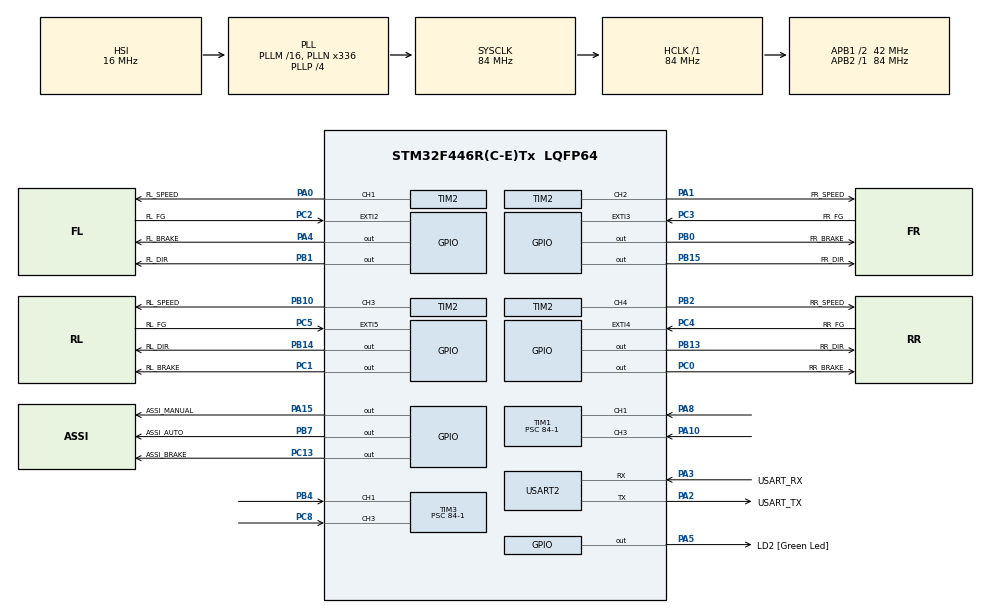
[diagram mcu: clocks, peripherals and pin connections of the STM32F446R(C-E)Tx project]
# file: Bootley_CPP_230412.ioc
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Dma.Request0=TIM1_CH1
Dma.Request1=TIM1_CH2
Dma.Request2=TIM1_CH3
Dma.Request3=TIM1_CH4/TRIG/COM
Dma.Request4=TIM3_CH1/TRIG
Dma.Request5=TIM3_CH2
Dma.Request6=TIM3_CH3
Dma.Request7=TIM3_CH4/UP
Dma.TIM1_CH1.0.Direction=DMA_PERIPH_TO_MEMORY
Dma.TIM1_CH1.0.FIFOMode=DMA_FIFOMODE_DISABLE
Dma.TIM1_CH1.0.Instance=DMA2_Stream1
Dma.TIM1_CH1.0.MemDataAlignment=DMA_MDATAALIGN_HALFWORD
Dma.TIM1_CH1.0.MemInc=DMA_MINC_ENABLE
Dma.TIM1_CH1.0.Mode=DMA_CIRCULAR
Dma.TIM1_CH1.0.PeriphDataAlignment=DMA_PDATAALIGN_HALFWORD
Dma.TIM1_CH1.0.PeriphInc=DMA_PINC_DISABLE
Dma.TIM1_CH1.0.Priority=DMA_PRIORITY_LOW
Dma.TIM1_CH2.1.Direction=DMA_PERIPH_TO_MEMORY
Dma.TIM1_CH2.1.FIFOMode=DMA_FIFOMODE_DISABLE
Dma.TIM1_CH2.1.Instance=DMA2_Stream2
Dma.TIM1_CH2.1.MemDataAlignment=DMA_MDATAALIGN_HALFWORD
Dma.TIM1_CH2.1.MemInc=DMA_MINC_ENABLE
Dma.TIM1_CH2.1.Mode=DMA_CIRCULAR
Dma.TIM1_CH2.1.PeriphDataAlignment=DMA_PDATAALIGN_HALFWORD
Dma.TIM1_CH2.1.PeriphInc=DMA_PINC_DISABLE
Dma.TIM1_CH2.1.Priority=DMA_PRIORITY_LOW
Dma.TIM1_CH3.2.Direction=DMA_PERIPH_TO_MEMORY
Dma.TIM1_CH3.2.FIFOMode=DMA_FIFOMODE_DISABLE
Dma.TIM1_CH3.2.Instance=DMA2_Stream6
Dma.TIM1_CH3.2.MemDataAlignment=DMA_MDATAALIGN_HALFWORD
Dma.TIM1_CH3.2.MemInc=DMA_MINC_ENABLE
Dma.TIM1_CH3.2.Mode=DMA_CIRCULAR
Dma.TIM1_CH3.2.PeriphDataAlignment=DMA_PDATAALIGN_HALFWORD
Dma.TIM1_CH3.2.PeriphInc=DMA_PINC_DISABLE
Dma.TIM1_CH3.2.Priority=DMA_PRIORITY_LOW
Dma.TIM1_CH4/TRIG/COM.3.Direction=DMA_PERIPH_TO_MEMORY
Dma.TIM1_CH4/TRIG/COM.3.FIFOMode=DMA_FIFOMODE_DISABLE
Dma.TIM1_CH4/TRIG/COM.3.Instance=DMA2_Stream4
Dma.TIM1_CH4/TRIG/COM.3.MemDataAlignment=DMA_MDATAALIGN_HALFWORD
Dma.TIM1_CH4/TRIG/COM.3.MemInc=DMA_MINC_ENABLE
Dma.TIM1_CH4/TRIG/COM.3.Mode=DMA_CIRCULAR
Dma.TIM1_CH4/TRIG/COM.3.PeriphDataAlignment=DMA_PDATAALIGN_HALFWORD
Dma.TIM1_CH4/TRIG/COM.3.PeriphInc=DMA_PINC_DISABLE
Dma.TIM1_CH4/TRIG/COM.3.Priority=DMA_PRIORITY_LOW
Dma.TIM3_CH1/TRIG.4.Direction=DMA_PERIPH_TO_MEMORY
Dma.TIM3_CH1/TRIG.4.FIFOMode=DMA_FIFOMODE_DISABLE
Dma.TIM3_CH1/TRIG.4.Instance=DMA1_Stream4
Dma.TIM3_CH1/TRIG.4.MemDataAlignment=DMA_MDATAALIGN_HALFWORD
Dma.TIM3_CH1/TRIG.4.MemInc=DMA_MINC_ENABLE
Dma.TIM3_CH1/TRIG.4.Mode=DMA_CIRCULAR
Dma.TIM3_CH1/TRIG.4.PeriphDataAlignment=DMA_PDATAALIGN_HALFWORD
Dma.TIM3_CH1/TRIG.4.PeriphInc=DMA_PINC_DISABLE
Dma.TIM3_CH1/TRIG.4.Priority=DMA_PRIORITY_LOW
Dma.TIM3_CH2.5.Direction=DMA_PERIPH_TO_MEMORY
Dma.TIM3_CH2.5.FIFOMode=DMA_FIFOMODE_DISABLE
Dma.TIM3_CH2.5.Instance=DMA1_Stream5
Dma.TIM3_CH2.5.MemDataAlignment=DMA_MDATAALIGN_HALFWORD
Dma.TIM3_CH2.5.MemInc=DMA_MINC_ENABLE
Dma.TIM3_CH2.5.Mode=DMA_CIRCULAR
Dma.TIM3_CH2.5.PeriphDataAlignment=DMA_PDATAALIGN_HALFWORD
Dma.TIM3_CH2.5.PeriphInc=DMA_PINC_DISABLE
Dma.TIM3_CH2.5.Priority=DMA_PRIORITY_LOW
Dma.TIM3_CH3.6.Direction=DMA_PERIPH_TO_MEMORY
Dma.TIM3_CH3.6.FIFOMode=DMA_FIFOMODE_DISABLE
Dma.TIM3_CH3.6.Instance=DMA1_Stream7
Dma.TIM3_CH3.6.MemDataAlignment=DMA_MDATAALIGN_HALFWORD
Dma.TIM3_CH3.6.MemInc=DMA_MINC_ENABLE
Dma.TIM3_CH3.6.Mode=DMA_CIRCULAR
Dma.TIM3_CH3.6.PeriphDataAlignment=DMA_PDATAALIGN_HALFWORD
Dma.TIM3_CH3.6.PeriphInc=DMA_PINC_DISABLE
Dma.TIM3_CH3.6.Priority=DMA_PRIORITY_LOW
Dma.TIM3_CH4/UP.7.Direction=DMA_PERIPH_TO_MEMORY
Dma.TIM3_CH4/UP.7.FIFOMode=DMA_FIFOMODE_DISABLE
Dma.TIM3_CH4/UP.7.Instance=DMA1_Stream2
Dma.TIM3_CH4/UP.7.MemDataAlignment=DMA_MDATAALIGN_HALFWORD
Dma.TIM3_CH4/UP.7.MemInc=DMA_MINC_ENABLE
Dma.TIM3_CH4/UP.7.Mode=DMA_CIRCULAR
Dma.TIM3_CH4/UP.7.PeriphDataAlignment=DMA_PDATAALIGN_HALFWORD
Dma.TIM3_CH4/UP.7.PeriphInc=DMA_PINC_DISABLE
Dma.TIM3_CH4/UP.7.Priority=DMA_PRIORITY_LOW
Mcu.Family=STM32F4
Mcu.Name=STM32F446R(C-E)Tx
Mcu.Package=LQFP64
NVIC.DMA1_Stream2_IRQn=true\:0\:0\:false\:false\:true\:false\:true\:true
NVIC.DMA1_Stream4_IRQn=true\:0\:0\:false\:false\:true\:false\:true\:true
NVIC.DMA1_Stream5_IRQn=true\:0\:0\:false\:false\:true\:false\:true\:true
NVIC.DMA1_Stream7_IRQn=true\:0\:0\:false\:false\:true\:false\:true\:true
NVIC.DMA2_Stream1_IRQn=true\:0\:0\:false\:false\:true\:false\:true\:true
NVIC.DMA2_Stream2_IRQn=true\:0\:0\:false\:false\:true\:false\:true\:true
NVIC.DMA2_Stream4_IRQn=true\:0\:0\:false\:false\:true\:false\:true\:true
NVIC.DMA2_Stream6_IRQn=true\:0\:0\:false\:false\:true\:false\:true\:true
NVIC.EXTI2_IRQn=true\:0\:0\:false\:false\:true\:true\:true\:true
NVIC.EXTI3_IRQn=true\:0\:0\:false\:false\:true\:true\:true\:true
NVIC.EXTI4_IRQn=true\:0\:0\:false\:false\:true\:true\:true\:true
NVIC.EXTI9_5_IRQn=true\:0\:0\:false\:false\:true\:true\:true\:true
NVIC.PriorityGroup=NVIC_PRIORITYGROUP_0
NVIC.TIM1_CC_IRQn=true\:0\:0\:false\:false\:true\:true\:true\:true
NVIC.TIM1_UP_TIM10_IRQn=true\:0\:0\:false\:false\:true\:true\:true\:true
NVIC.TIM3_IRQn=true\:0\:0\:false\:false\:true\:true\:true\:true
PA0-WKUP.GPIO_Label=FL_SPEED
PA0-WKUP.Signal=S_TIM2_CH1_ETR
PA1.GPIO_Label=FR_SPEED
PA1.Signal=S_TIM2_CH2
PA10.Signal=S_TIM1_CH3
PA13.GPIO_Label=TMS
PA13.Mode=Serial_Wire
PA13.Signal=SYS_JTMS-SWDIO
PA14.GPIO_Label=TCK
PA14.Mode=Serial_Wire
PA14.Signal=SYS_JTCK-SWCLK
PA15.GPIO_Label=ASSI_MANUAL
PA15.Signal=GPIO_Output
PA2.GPIO_Label=USART_TX
PA2.Mode=Asynchronous
PA2.Signal=USART2_TX
PA3.GPIO_Label=USART_RX
PA3.Mode=Asynchronous
PA3.Signal=USART2_RX
PA4.GPIO_Label=FL_BRAKE
PA4.Signal=GPIO_Output
PA5.GPIO_Label=LD2 [Green Led]
PA5.Signal=GPIO_Output
PA8.Signal=S_TIM1_CH1
PB0.GPIO_Label=FR_BRAKE
PB0.Signal=GPIO_Output
PB1.GPIO_Label=FL_DIR
PB1.Signal=GPIO_Output
PB10.GPIO_Label=RL_SPEED
PB10.Signal=S_TIM2_CH3
PB13.GPIO_Label=RR_DIR
PB13.Signal=GPIO_Output
PB14.GPIO_Label=RL_DIR
PB14.Signal=GPIO_Output
PB15.GPIO_Label=FR_DIR
PB15.Signal=GPIO_Output
PB2.GPIO_Label=RR_SPEED
PB2.Signal=S_TIM2_CH4
PB3.GPIO_Label=SWO
PB3.Signal=SYS_JTDO-SWO
PB4.Signal=S_TIM3_CH1
PB7.GPIO_Label=ASSI_AUTO
PB7.Signal=GPIO_Output
PC0.GPIO_Label=RR_BRAKE
PC0.Signal=GPIO_Output
PC1.GPIO_Label=RL_BRAKE
PC1.Signal=GPIO_Output
PC13.GPIO_Label=ASSI_BRAKE
PC13.Signal=GPIO_Output
PC14-OSC32_IN.Mode=LSE-External-Oscillator
PC14-OSC32_IN.Signal=RCC_OSC32_IN
PC15-OSC32_OUT.Mode=LSE-External-Oscillator
PC15-OSC32_OUT.Signal=RCC_OSC32_OUT
PC2.GPIO_Label=FL_FG
PC2.GPIO_ModeDefaultEXTI=GPIO_MODE_IT_RISING_FALLING
PC2.Signal=GPXTI2
PC3.GPIO_Label=FR_FG
PC3.GPIO_ModeDefaultEXTI=GPIO_MODE_IT_RISING_FALLING
PC3.Signal=GPXTI3
PC4.GPIO_Label=RR_FG
PC4.GPIO_ModeDefaultEXTI=GPIO_MODE_IT_RISING_FALLING
PC4.Signal=GPXTI4
PC5.GPIO_Label=RL_FG
PC5.GPIO_ModeDefaultEXTI=GPIO_MODE_IT_RISING_FALLING
PC5.Signal=GPXTI5
PC8.Signal=S_TIM3_CH3
PH0-OSC_IN.Mode=HSE-External-Oscillator
PH0-OSC_IN.Signal=RCC_OSC_IN
PH1-OSC_OUT.Mode=HSE-External-Oscillator
PH1-OSC_OUT.Signal=RCC_OSC_OUT
ProjectManager.HeapSize=0x200
ProjectManager.StackSize=0x400
ProjectManager.TargetToolchain=STM32CubeIDE
RCC.48MHZClocksFreq_Value=84000000
RCC.AHBFreq_Value=84000000
RCC.APB1CLKDivider=RCC_HCLK_DIV2
RCC.APB1Freq_Value=42000000
RCC.APB1TimFreq_Value=84000000
RCC.APB2Freq_Value=84000000
RCC.APB2TimFreq_Value=84000000
RCC.CortexFreq_Value=84000000
RCC.FLatency-AdvancedSettings=FLASH_LATENCY_2
RCC.HCLKFreq_Value=84000000
RCC.HSE_VALUE=8000000
RCC.HSI_VALUE=16000000
RCC.PLLN=336
RCC.PLLP=RCC_PLLP_DIV4
RCC.SYSCLKFreq_VALUE=84000000
RCC.SYSCLKSource=RCC_SYSCLKSOURCE_PLLCLK
RCC.USBFreq_Value=168000000
RCC.VCOOutputFreq_Value=336000000
SH.S_TIM1_CH1.0=TIM1_CH1,Input_Capture1_from_TI1
SH.S_TIM1_CH3.0=TIM1_CH3,Input_Capture3_from_TI3
SH.S_TIM2_CH1_ETR.0=TIM2_CH1,PWM Generation1 CH1
SH.S_TIM2_CH2.0=TIM2_CH2,PWM Generation2 CH2
SH.S_TIM2_CH3.0=TIM2_CH3,PWM Generation3 CH3
SH.S_TIM2_CH4.0=TIM2_CH4,PWM Generation4 CH4
SH.S_TIM3_CH1.0=TIM3_CH1,Input_Capture1_from_TI1
SH.S_TIM3_CH3.0=TIM3_CH3,Input_Capture3_from_TI3
TIM1.Channel-Input_Capture1_from_TI1=TIM_CHANNEL_1
TIM1.Channel-Input_Capture2_from_TI1_63=TIM_CHANNEL_2
TIM1.Channel-Input_Capture3_from_TI3=TIM_CHANNEL_3
TIM1.Channel-Input_Capture4_from_TI3_63=TIM_CHANNEL_4
TIM1.ICFilter_CH1=15
TIM1.ICFilter_CH3=15
TIM1.ICPolarity_CH2=TIM_INPUTCHANNELPOLARITY_FALLING
TIM1.ICPolarity_CH4=TIM_INPUTCHANNELPOLARITY_FALLING
TIM1.Prescaler=84-1
TIM10.Period=5000-1
TIM10.Prescaler=840-1
TIM2.Channel-PWM\ Generation1\ CH1=TIM_CHANNEL_1
TIM2.Channel-PWM\ Generation2\ CH2=TIM_CHANNEL_2
TIM2.Channel-PWM\ Generation3\ CH3=TIM_CHANNEL_3
TIM2.Channel-PWM\ Generation4\ CH4=TIM_CHANNEL_4
TIM2.Period=820
TIM2.Prescaler=4
TIM2.Pulse-PWM\ Generation1\ CH1=900
TIM2.Pulse-PWM\ Generation2\ CH2=900
TIM2.Pulse-PWM\ Generation3\ CH3=900
TIM2.Pulse-PWM\ Generation4\ CH4=900
TIM3.Channel-Input_Capture1_from_TI1=TIM_CHANNEL_1
TIM3.Channel-Input_Capture2_from_TI1_63=TIM_CHANNEL_2
TIM3.Channel-Input_Capture3_from_TI3=TIM_CHANNEL_3
TIM3.Channel-Input_Capture4_from_TI3_63=TIM_CHANNEL_4
TIM3.ICFilter_CH1=15
TIM3.ICFilter_CH3=15
TIM3.ICPolarity_CH2=TIM_INPUTCHANNELPOLARITY_FALLING
TIM3.ICPolarity_CH4=TIM_INPUTCHANNELPOLARITY_FALLING
TIM3.Prescaler=84-1
USART2.VirtualMode=VM_ASYNC
VP_TIM10_VS_ClockSourceINT.Mode=Enable_Timer
VP_TIM1_VS_ClockSourceINT.Mode=Internal
VP_TIM1_VS_indirect_ch1.Mode=Input_Capture2_from_TI1_63
VP_TIM1_VS_indirect_ch3.Mode=Input_Capture4_from_TI3_63
VP_TIM2_VS_ClockSourceINT.Mode=Internal
VP_TIM3_VS_ClockSourceINT.Mode=Internal
VP_TIM3_VS_indirect_ch1.Mode=Input_Capture2_from_TI1_63
VP_TIM3_VS_indirect_ch3.Mode=Input_Capture4_from_TI3_63
board=NUCLEO-F446RE

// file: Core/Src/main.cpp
/* USER CODE BEGIN Header */
/**
  ******************************************************************************
  * @file           : main.c
  * @brief          : Main program body
  ******************************************************************************
  * @attention
  *
  * Copyright (c) 2023 STMicroelectronics.
  * All rights reserved.
  *
  * This software is licensed under terms that can be found in the LICENSE file
  * in the root directory of this software component.
  * If no LICENSE file comes with this software, it is provided AS-IS.
  *
  ******************************************************************************
  */
/* USER CODE END Header */
#include "main.h"
#include "dma.h"
#include "tim.h"
#include "usart.h"
#include "gpio.h"

/* USER CODE BEGIN Includes */
#include "Bootley.hpp"
/* USER CODE END Includes */

void SystemClock_Config(void);

int main(void)
{

  /* MCU Configuration--------------------------------------------------------*/

  /* Reset of all peripherals, Initializes the Flash interface and the Systick. */
  HAL_Init();

  /* Configure the system clock */
  SystemClock_Config();

  /* Initialize all configured peripherals */
  MX_GPIO_Init();
  MX_DMA_Init();
  MX_USART2_UART_Init();
  MX_TIM1_Init();
  MX_TIM2_Init();
  MX_TIM3_Init();
  MX_TIM10_Init();
  /* USER CODE BEGIN 2 */

	  Bootley bootley;
	  bootley.InitModule();

  /* USER CODE END 2 */

  /* Infinite loop */
  while (1)
  {

    /* USER CODE BEGIN 3 */

//	  check_IC();
	  bootley.SetCarState();
	  bootley.Drive();

  }
  /* USER CODE END 3 */
}

void SystemClock_Config(void)
{
  RCC_OscInitTypeDef RCC_OscInitStruct = {0};
  RCC_ClkInitTypeDef RCC_ClkInitStruct = {0};

  /** Configure the main internal regulator output voltage
  */
  __HAL_RCC_PWR_CLK_ENABLE();
  __HAL_PWR_VOLTAGESCALING_CONFIG(PWR_REGULATOR_VOLTAGE_SCALE3);

  /** Initializes the RCC Oscillators according to the specified parameters
  * in the RCC_OscInitTypeDef structure.
  */
  RCC_OscInitStruct.OscillatorType = RCC_OSCILLATORTYPE_HSI;
  RCC_OscInitStruct.HSIState = RCC_HSI_ON;
  RCC_OscInitStruct.HSICalibrationValue = RCC_HSICALIBRATION_DEFAULT;
  RCC_OscInitStruct.PLL.PLLState = RCC_PLL_ON;
  RCC_OscInitStruct.PLL.PLLSource = RCC_PLLSOURCE_HSI;
  RCC_OscInitStruct.PLL.PLLM = 16;
  RCC_OscInitStruct.PLL.PLLN = 336;
  RCC_OscInitStruct.PLL.PLLP = RCC_PLLP_DIV4;
  RCC_OscInitStruct.PLL.PLLQ = 2;
  RCC_OscInitStruct.PLL.PLLR = 2;
  if (HAL_RCC_OscConfig(&RCC_OscInitStruct) != HAL_OK)
  {
    Error_Handler();
  }

  /** Initializes the CPU, AHB and APB buses clocks
  */
  RCC_ClkInitStruct.ClockType = RCC_CLOCKTYPE_HCLK|RCC_CLOCKTYPE_SYSCLK
                              |RCC_CLOCKTYPE_PCLK1|RCC_CLOCKTYPE_PCLK2;
  RCC_ClkInitStruct.SYSCLKSource = RCC_SYSCLKSOURCE_PLLCLK;
  RCC_ClkInitStruct.AHBCLKDivider = RCC_SYSCLK_DIV1;
  RCC_ClkInitStruct.APB1CLKDivider = RCC_HCLK_DIV2;
  RCC_ClkInitStruct.APB2CLKDivider = RCC_HCLK_DIV1;

  if (HAL_RCC_ClockConfig(&RCC_ClkInitStruct, FLASH_LATENCY_2) != HAL_OK)
  {
    Error_Handler();
  }
}

void Error_Handler(void)
{
  __disable_irq();
  while (1)
  {
  }
}
